VERSION "created by canmatrix"

NS_ :

BS_:

BU_: Acc

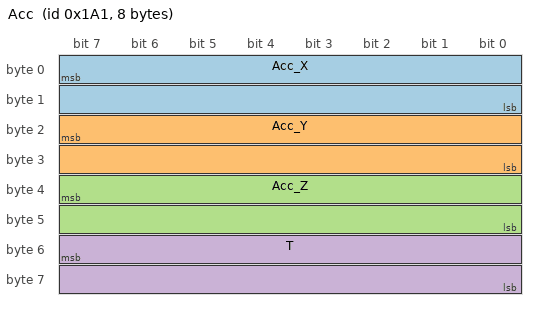
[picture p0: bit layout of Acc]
BO_ 417 Acc: 8 Acc
 SG_ Acc_X : 7|16@0- (0.00133333,0) [-40|40] "g" Vector__XXX
 SG_ Acc_Y : 23|16@0- (0.00133333,0) [-40|40] "g" Vector__XXX
 SG_ Acc_Z : 39|16@0- (0.00133333,0) [-40|40] "g" Vector__XXX
 SG_ T : 55|16@0- (0.01,0) [0|0] "C" Vector__XXX
